NS_ :

BS_:

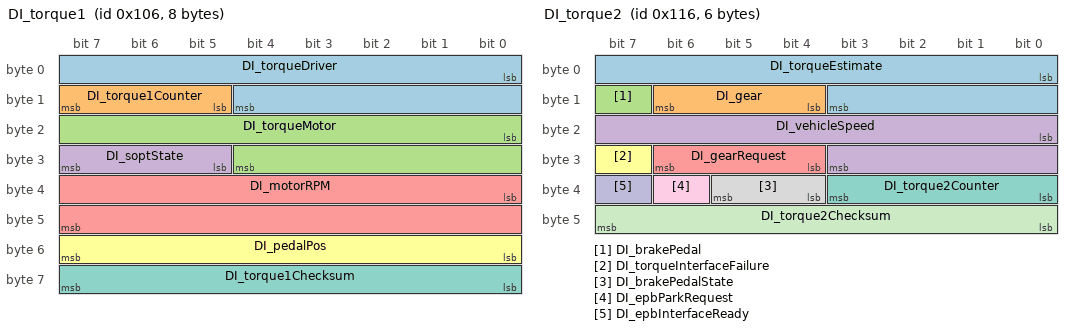
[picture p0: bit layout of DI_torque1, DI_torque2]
BO_ 262 DI_torque1: 8 DI
 SG_ DI_torqueDriver : 0|13@1- (0.25,0) [-750|750] "Nm"  NEO
 SG_ DI_torque1Counter : 13|3@1+ (1,0) [0|0] ""  NEO
 SG_ DI_torqueMotor : 16|13@1- (0.25,0) [-750|750] "Nm"  NEO
 SG_ DI_soptState : 29|3@1+ (1,0) [0|0] ""  NEO
 SG_ DI_motorRPM : 32|16@1- (1,0) [-17000|17000] "RPM"  NEO
 SG_ DI_pedalPos : 48|8@1+ (0.4,0) [0|100] "%"  NEO
 SG_ DI_torque1Checksum : 56|8@1+ (1,0) [0|0] ""  NEO

BO_ 278 DI_torque2: 6 DI
 SG_ DI_torqueEstimate : 0|12@1- (0.5,0) [-750|750] "Nm" NEO
 SG_ DI_gear : 12|3@1+ (1,0) [0|0] "" NEO
 SG_ DI_brakePedal : 15|1@1+ (1,0) [0|0] "" NEO
 SG_ DI_vehicleSpeed : 16|12@1+ (0.05,-25) [-25|179.75] "MPH" NEO
 SG_ DI_gearRequest : 28|3@1+ (1,0) [0|0] "" NEO
 SG_ DI_torqueInterfaceFailure : 31|1@1+ (1,0) [0|0] "" NEO
 SG_ DI_torque2Counter : 32|4@1+ (1,0) [0|0] "" NEO
 SG_ DI_brakePedalState : 36|2@1+ (1,0) [0|0] "" NEO
 SG_ DI_epbParkRequest : 38|1@1+ (1,0) [0|0] "" NEO
 SG_ DI_epbInterfaceReady : 39|1@1+ (1,0) [0|0] "" NEO
 SG_ DI_torque2Checksum : 40|8@1+ (1,0) [0|0] "" NEO

BO_ 504 BrakeMessage: 8 XXX
 SG_ driverBrakeStatus : 2|2@1+ (1,0) [0|3] "" XXX

BO_ 568 STW_ACTN_RQ: 8 STW
 SG_ SpdCtrlLvr_Stat : 0|6@1+ (1,0) [0|0] "" NEO
 SG_ VSL_Enbl_Rq : 6|1@1+ (1,0) [0|0] "" NEO
 SG_ SpdCtrlLvrStat_Inv : 7|1@1+ (1,0) [0|0] "" NEO
 SG_ DTR_Dist_Rq : 8|8@1+ (1,0) [0|200] "" NEO
 SG_ TurnIndLvr_Stat : 16|2@1+ (1,0) [0|0] "" NEO
 SG_ HiBmLvr_Stat : 18|2@1+ (1,0) [0|0] "" NEO
 SG_ WprWashSw_Psd : 20|2@1+ (1,0) [0|0] "" NEO
 SG_ WprWash_R_Sw_Posn_V2 : 22|2@1+ (1,0) [0|0] "" NEO
 SG_ StW_Lvr_Stat : 24|3@1+ (1,0) [0|0] "" NEO
 SG_ StW_Cond_Flt : 27|1@1+ (1,0) [0|0] "" NEO
 SG_ StW_Cond_Psd : 28|2@1+ (1,0) [0|0] "" NEO
 SG_ HrnSw_Psd : 30|2@1+ (1,0) [0|0] "" NEO
 SG_ StW_Sw00_Psd : 32|1@1+ (1,0) [0|0] "" NEO
 SG_ StW_Sw01_Psd : 33|1@1+ (1,0) [0|0] "" NEO
 SG_ StW_Sw02_Psd : 34|1@1+ (1,0) [0|0] "" NEO
 SG_ StW_Sw03_Psd : 35|1@1+ (1,0) [0|0] "" NEO
 SG_ StW_Sw04_Psd : 36|1@1+ (1,0) [0|0] "" NEO
 SG_ StW_Sw05_Psd : 37|1@1+ (1,0) [0|0] "" NEO
 SG_ StW_Sw06_Psd : 38|1@1+ (1,0) [0|0] "" NEO
 SG_ StW_Sw07_Psd : 39|1@1+ (1,0) [0|0] "" NEO
 SG_ StW_Sw08_Psd : 40|1@1+ (1,0) [0|0] "" NEO
 SG_ StW_Sw09_Psd : 41|1@1+ (1,0) [0|0] "" NEO
 SG_ StW_Sw10_Psd : 42|1@1+ (1,0) [0|0] "" NEO
 SG_ StW_Sw11_Psd : 43|1@1+ (1,0) [0|0] "" NEO
 SG_ StW_Sw12_Psd : 44|1@1+ (1,0) [0|0] "" NEO
 SG_ StW_Sw13_Psd : 45|1@1+ (1,0) [0|0] "" NEO
 SG_ StW_Sw14_Psd : 46|1@1+ (1,0) [0|0] "" NEO
 SG_ StW_Sw15_Psd : 47|1@1+ (1,0) [0|0] "" NEO
 SG_ WprSw6Posn : 48|3@1+ (1,0) [0|0] "" NEO
 SG_ MC_STW_ACTN_RQ : 52|4@1+ (1,0) [0|15] "" NEO
 SG_ CRC_STW_ACTN_RQ : 56|8@1+ (1,0) [0|0] "" NEO

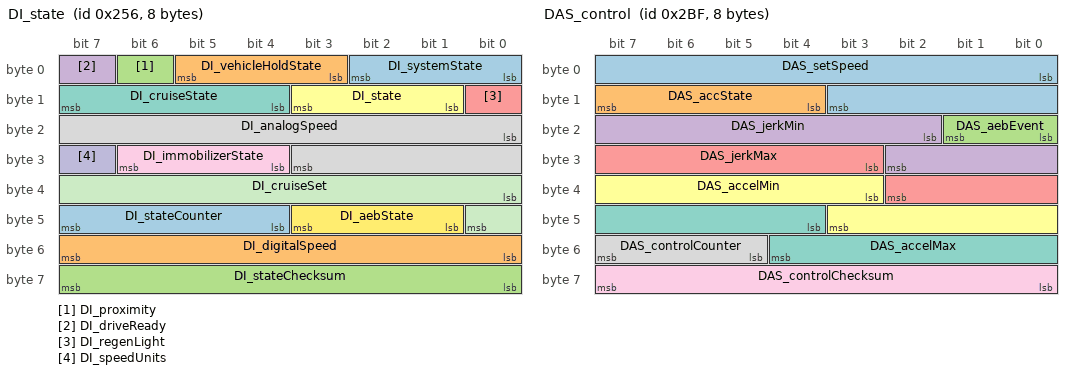
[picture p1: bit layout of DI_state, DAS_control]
BO_ 598 DI_state: 8 DI
 SG_ DI_systemState : 0|3@1+ (1,0) [0|0] ""  NEO
 SG_ DI_vehicleHoldState : 3|3@1+ (1,0) [0|0] ""  NEO
 SG_ DI_proximity : 6|1@1+ (1,0) [0|0] ""  NEO
 SG_ DI_driveReady : 7|1@1+ (1,0) [0|0] ""  NEO
 SG_ DI_regenLight : 8|1@1+ (1,0) [0|0] ""  NEO
 SG_ DI_state : 9|3@1+ (1,0) [0|0] ""  NEO
 SG_ DI_cruiseState : 12|4@1+ (1,0) [0|0] ""  NEO
 SG_ DI_analogSpeed : 16|12@1+ (0.1,0) [0|150] "speed"  NEO
 SG_ DI_immobilizerState : 28|3@1+ (1,0) [0|0] ""  NEO
 SG_ DI_speedUnits : 31|1@1+ (1,0) [0|1] ""  NEO
 SG_ DI_cruiseSet : 32|9@1+ (0.5,0) [0|255.5] "speed"  NEO
 SG_ DI_aebState : 41|3@1+ (1,0) [0|0] ""  NEO
 SG_ DI_stateCounter : 44|4@1+ (1,0) [0|0] ""  NEO
 SG_ DI_digitalSpeed : 48|8@1+ (1,0) [0|250] ""  NEO
 SG_ DI_stateChecksum : 56|8@1+ (1,0) [0|0] ""  NEO

BO_ 703 DAS_control: 8 GTW
 SG_ DAS_setSpeed : 0|12@1+ (0.1,0) [0|409.4] "kph" DI,PM,APS
 SG_ DAS_accState : 12|4@1+ (1,0) [0|0] "" DI,PM,APS
 SG_ DAS_aebEvent : 16|2@1+ (1,0) [0|3] "" DI,PM,APS
 SG_ DAS_jerkMin : 18|9@1+ (0.03,-15.232) [-15.232|0.098] "m/s^3" DI,PM,APS
 SG_ DAS_jerkMax : 27|8@1+ (0.059,0) [0|15.045] "m/s^3" DI,PM,APS
 SG_ DAS_accelMin : 35|9@1+ (0.04,-15) [-15|5.44] "m/s^2" DI,PM,APS
 SG_ DAS_accelMax : 44|9@1+ (0.04,-15) [-15|5.44] "m/s^2" DI,PM,APS
 SG_ DAS_controlCounter : 53|3@1+ (1,0) [0|0] "" DI,PM,APS
 SG_ DAS_controlChecksum : 56|8@1+ (1,0) [0|0] "" DI,PM,APS

BU_: K182_PACM K43_PSCM K17_EBCM NEO K124_ASCM

CM_ "AUTOGENERATED FILE, DO NOT EDIT";

CM_ "Imported file _stellantis_common.dbc starts here";
CM_ SG_ 258 STEERING_ANGLE_HP "Steering angle high precision";
CM_ SG_ 264 ENGINE_TORQUE "Effective engine torque";
CM_ SG_ 264 EXPECTED_ENGINE_TORQUE "Expected Engine Torque based on target engine speed";
CM_ SG_ 678 LKAS_ICON_COLOR "3 is yellow, 2 is green, 1 is white, 0 is null";
CM_ SG_ 678 LKAS_LANE_LINES "0x01 transparent lines, 0x02 left white, 0x03 right white, 0x04 left yellow with car on top, 0x05 left yellow with car on top, 0x06 both white, 0x07 left yellow, 0x08 left yellow right white, 0x09 right yellow, 0x0a right yellow left white, 0x0b left yellow with car on top right white, 0x0c right yellow with car on top left white, (0x00, 0x0d, 0x0e, 0x0f) null";
CM_ SG_ 678 LKAS_ALERTS "(0x01, 0x02) lane sense off, (0x03, 0x04, 0x06) place hands on steering wheel, 0x07 lane departure detected + place hands on steering wheel, (0x08, 0x09) lane sense unavailable + clean front windshield, 0x0b lane sense and auto high beam unavailable + clean front windshield, 0x0c lane sense unavailable + service required, (0x00, 0x05, 0x0a, 0x0d, 0x0e, 0x0f) null";

CM_ "chrysler_pacifica_2017_hybrid.dbc starts here";

CM_ SG_ 653 BRAKE_PRESSURE "max seems to be 148";
CM_ SG_ 746 PRNDL "5=L, 4=D, 3=N, 2=R, 1=P";
CM_ SG_ 320 BRAKE_PRESSED_2 "Value is 5 when brake is pressed by human, 1 when ACC brake";
CM_ SG_ 320 BRAKE_PRESSED_ACC "set when ACC brakes";
CM_ SG_ 792 TURN_SIGNALS "1=Left, 2=Right";
CM_ SG_ 264 ACCEL_PEDAL "not in ACC so seems to be actual pedal. Use for gasPressed";
CM_ SG_ 544 LKAS_STATE "2 when autopark has control, 8 when is actuatable by lkas, 4 when there is a fault";
CM_ SG_ 658 LKAS_STEERING_TORQUE "Most sent by stock system is 1024+-230. + is left. typically changes by 2 or 3 each 0.01s";
CM_ SG_ 678 LKAS_ICON_COLOR "3 is yellow, 2 is green, 1 is white, 0 is null";
CM_ SG_ 678 LKAS_LANE_LINES "0x01 transparent lines, 0x02 left white, 0x03 right white, 0x04 left yellow with car on top, 0x05 left yellow with car on top, 0x06 both white, 0x07 left yellow, 0x08 left yellow right white, 0x09 right yellow, 0x0a right yellow left white, 0x0b left yellow with car on top right white, 0x0c right yellow with car on top left white, (0x00, 0x0d, 0x0e, 0x0f) null";
CM_ SG_ 678 LKAS_ALERTS "(0x01, 0x02) lane sense off, (0x03, 0x04, 0x06) place hands on steering wheel, 0x07 lane departure detected + place hands on steering wheel, (0x08, 0x09) lane sense unavailable + clean front windshield, 0x0b lane sense and auto high beam unavailable + clean front windshield, 0x0c lane sense unavailable + service required, (0x00, 0x05, 0x0a, 0x0d, 0x0e, 0x0f) null";
CM_ SG_ 705 AUTO_PARK_TOGGLE_1 "set briefly when turning on or off self-parking";
CM_ SG_ 671 AUTO_PARK_CMD "Request Appears to be in NM";
CM_ SG_ 671 AUTO_PARK_STATUS "1 = IDLE / NO REQUEST 9 = START REQUEST 10 = REQUEST MODE 11 = REQUEST MODE";
CM_ SG_ 826 AUTO_PARK_GEAR_1 "Reverse=0, Forward=f";
CM_ SG_ 826 AUTO_PARK_GEAR_2 "Reverse=0, Forward=f";
CM_ SG_ 826 AUTO_PARK_GEAR_3 "Reverse=0, Forward=f";
CM_ SG_ 332 STEER_ANGLE_2 "slightly lags the other steer_angle signal. also more noisy.";
CM_ SG_ 608 PARKSENSE_DISABLED "set if parksense is disabled";
CM_ SG_ 729 LKAS_STATUS_OK "Set to 0x0820 when LKAS system is plugged in.";
CM_ SG_ 825 BEEP_339 "sent every 0.5s. 0050 is no beep. To beep send 4355 or 4155. Used by ParkSense warning.";
CM_ SG_ 270 ELECTRIC_MOTOR "0x7fff indicates electric motor not in use";
CM_ SG_ 291 ENERGY_GAIN_LOSS "unsure what this actually is";
CM_ SG_ 291 ENERGY_SMOOTHER_CURVE "unsure what it is, but smoother";
CM_ SG_ 308 ACCEL_134 "only set when human presses accel pedal";
CM_ SG_ 532 NOISY_SLOWLY_DECREASING "perhaps battery but do not know";
CM_ SG_ 816 TRACTION_OFF "set when traction off button is enabled";
CM_ SG_ 816 TOGGLE_PARKSENSE "sending 3000071ec0ff9000 enables or disables parksense";
CM_ SG_ 324 SPEED_2 "signal is approx half other speeds";
CM_ SG_ 501 ACC_SPEED_CONFIG_KPH "speed configured for ACC";
CM_ SG_ 501 ACC_SPEED_CONFIG_MPH "speed configured for ACC";
CM_ SG_ 501 CRUISE_STATE "may just be an icon, but seems to indicate different cruise modes: ACC and Non-ACC and engaged state for both.";
CM_ SG_ 625 SPEED "zero on non-acc drives";

VAL_ 544 AEB_Status 12 "AEB related" 8 "AEB actuation" 4 "AEB related" 0 "No AEB actuation";
